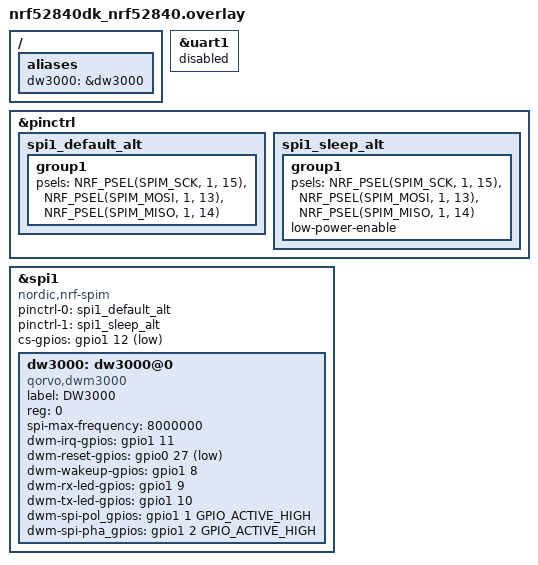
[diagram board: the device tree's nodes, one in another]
/* GEREKLİ KÜTÜPHANELER */
#include <zephyr/dt-bindings/pinctrl/nrf-pinctrl.h>
#include <zephyr/dt-bindings/gpio/gpio.h>

/ {
    aliases {
        dw3000 = &dw3000;
    };
};

/* --- SENİN ORİJİNAL KODUN: UART1'İ KAPAT Kİ P1.01 VE P1.02 BOŞA ÇIKSIN --- */
&uart1 {
    status = "disabled";
};

/* --- SPI PİNLERİ (nRF52840DK Arduino Header'larına Göre) --- */
&pinctrl {
    spi1_default_alt: spi1_default_alt {
        group1 {
            psels = <NRF_PSEL(SPIM_SCK, 1, 15)>,
                    <NRF_PSEL(SPIM_MOSI, 1, 13)>,
                    <NRF_PSEL(SPIM_MISO, 1, 14)>;
        };
    };

    spi1_sleep_alt: spi1_sleep_alt {
        group1 {
            psels = <NRF_PSEL(SPIM_SCK, 1, 15)>,
                    <NRF_PSEL(SPIM_MOSI, 1, 13)>,
                    <NRF_PSEL(SPIM_MISO, 1, 14)>;
            low-power-enable;
        };
    };
};

/* --- SPI VE UWB MODÜLÜ --- */
&spi1 {
    compatible = "nordic,nrf-spim";
    status = "okay";
    
    #address-cells = <1>;
    #size-cells = <0>;
    
    pinctrl-0 = <&spi1_default_alt>;
    pinctrl-1 = <&spi1_sleep_alt>;
    pinctrl-names = "default", "sleep";
    
    cs-gpios = <&gpio1 12 (GPIO_ACTIVE_LOW | GPIO_PULL_UP)>;

    dw3000: dw3000@0 {
        compatible = "qorvo,dwm3000";
        label = "DW3000";
        reg = <0>;
        spi-max-frequency = <8000000>;
        
        /* port.c dosyasının ısrarla aradığı DWM3000 EVB Shield pinleri */
        dwm-irq-gpios = <&gpio1 11 (GPIO_ACTIVE_HIGH | GPIO_PULL_DOWN)>;
        dwm-reset-gpios = <&gpio0 27 (GPIO_ACTIVE_LOW | GPIO_PULL_UP)>;
        dwm-wakeup-gpios = <&gpio1 8 GPIO_ACTIVE_HIGH>;
        dwm-rx-led-gpios = <&gpio1 9 GPIO_ACTIVE_HIGH>;
        dwm-tx-led-gpios = <&gpio1 10 GPIO_ACTIVE_HIGH>;
        
        /* İŞTE SENİN BOŞA ÇIKARTTIĞIN PİNLERİ BURADA DWM3000'E VERİYORUZ! */
        dwm-spi-pol_gpios = <&gpio1 1 GPIO_ACTIVE_HIGH>; /* P1.01 */
        dwm-spi-pha_gpios = <&gpio1 2 GPIO_ACTIVE_HIGH>; /* P1.02 */
        
        status = "okay";
    };
};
